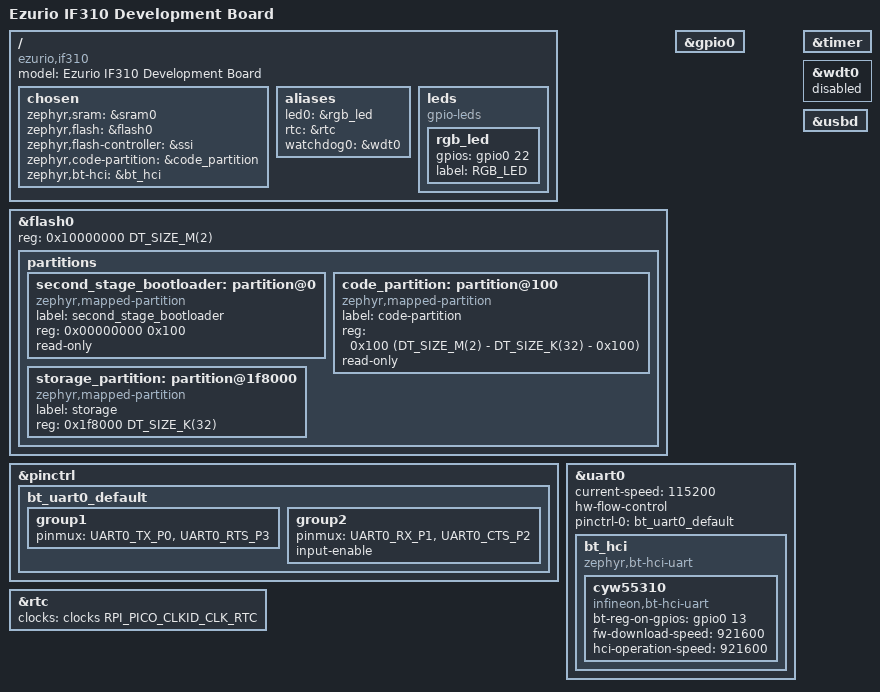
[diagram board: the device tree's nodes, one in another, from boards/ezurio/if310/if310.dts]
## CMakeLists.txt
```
cmake_minimum_required(VERSION 3.13)

set(CMAKE_EXPORT_COMPILE_COMMANDS ON)
list(APPEND BOARD_ROOT ${CMAKE_CURRENT_SOURCE_DIR})

get_filename_component(BTSTACK_ROOT "${CMAKE_CURRENT_SOURCE_DIR}/../.." ABSOLUTE)
if(DEFINED ENV{BTSTACK_ROOT})
    set(BTSTACK_ROOT "$ENV{BTSTACK_ROOT}")
endif()

include("${BTSTACK_ROOT}/chipset/bcm/btstack_bcm_patchram.cmake")

set(BTSTACK_ZEPHYR_PATCHRAM_CHIPSETS)
if(BOARD MATCHES "^if310($|/)")
    list(APPEND BTSTACK_ZEPHYR_PATCHRAM_CHIPSETS CYW55310)
elseif(BOARD MATCHES "^nucleo_(f439zi|h563zi|h753zi)($|/)")
    # Provide both firmware choices documented in the Nucleo configurations.
    list(APPEND BTSTACK_ZEPHYR_PATCHRAM_CHIPSETS CYW55513 CYW55573)
endif()

foreach(chipset IN LISTS BTSTACK_ZEPHYR_PATCHRAM_CHIPSETS)
    set(BTSTACK_ZEPHYR_PATCHRAM_FILE "${BTSTACK_${chipset}_PATCHRAM_FILE}")
    set(BTSTACK_ZEPHYR_PATCHRAM_URL "${BTSTACK_${chipset}_PATCHRAM_URL}")
    set(BTSTACK_ZEPHYR_PATCHRAM_SHA256 "${BTSTACK_${chipset}_PATCHRAM_SHA256}")
    set(BTSTACK_ZEPHYR_PATCHRAM_PATH "${CMAKE_CURRENT_SOURCE_DIR}/${BTSTACK_ZEPHYR_PATCHRAM_FILE}")
    if(NOT EXISTS "${BTSTACK_ZEPHYR_PATCHRAM_PATH}")
        message(STATUS "Downloading ${BTSTACK_ZEPHYR_PATCHRAM_FILE}")
        file(DOWNLOAD
            "${BTSTACK_ZEPHYR_PATCHRAM_URL}"
            "${BTSTACK_ZEPHYR_PATCHRAM_PATH}"
            EXPECTED_HASH SHA256=${BTSTACK_ZEPHYR_PATCHRAM_SHA256}
            STATUS BTSTACK_ZEPHYR_PATCHRAM_DOWNLOAD_STATUS)
        list(GET BTSTACK_ZEPHYR_PATCHRAM_DOWNLOAD_STATUS 0 BTSTACK_ZEPHYR_PATCHRAM_DOWNLOAD_RESULT)
        if(NOT BTSTACK_ZEPHYR_PATCHRAM_DOWNLOAD_RESULT EQUAL 0)
            list(GET BTSTACK_ZEPHYR_PATCHRAM_DOWNLOAD_STATUS 1 BTSTACK_ZEPHYR_PATCHRAM_DOWNLOAD_ERROR)
            file(REMOVE "${BTSTACK_ZEPHYR_PATCHRAM_PATH}")
            message(FATAL_ERROR "Failed to download ${BTSTACK_ZEPHYR_PATCHRAM_FILE}: ${BTSTACK_ZEPHYR_PATCHRAM_DOWNLOAD_ERROR}")
        endif()
    endif()
endforeach()

find_package(Zephyr REQUIRED HINTS $ENV{ZEPHYR_BASE})
project(BTstack-Zephyr)

find_package(Python3 REQUIRED COMPONENTS Interpreter)
include("${BTSTACK_ROOT}/tool/cmake/BTstack.cmake")
include("${BTSTACK_ROOT}/example/requirements.cmake")

btstack_declare_port(zephyr)
btstack_collect_public_include_directories(BTSTACK_ZEPHYR_PUBLIC_INCLUDE_DIRECTORIES)

# Zephyr normally force-includes autoconf.h for compilation. Include it
# explicitly while extracting btstack_config.h's ENABLE_*/HAVE_* macros so the
# resolver sees the same Kconfig values as the compiler.
btstack_configure_port(OUTPUT BTSTACK_ZEPHYR_CONFIGURATION_MACROS
    CONFIG "${CMAKE_CURRENT_SOURCE_DIR}/btstack_config.h"
    INCLUDE_DIRECTORIES "${CMAKE_CURRENT_BINARY_DIR}/zephyr/include/generated")
# Zephyr normally reconfigures after Kconfig changes; retain the generated
# header explicitly because it directly controls resolver selection.
set_property(DIRECTORY APPEND PROPERTY CMAKE_CONFIGURE_DEPENDS
    "${CMAKE_CURRENT_BINARY_DIR}/zephyr/include/generated/zephyr/autoconf.h")

string(JOIN ", " BTSTACK_ZEPHYR_CONFIGURATION_MACROS_DISPLAY ${BTSTACK_ZEPHYR_CONFIGURATION_MACROS})
message(STATUS "BTstack config ENABLE_*/HAVE_* macros: ${BTSTACK_ZEPHYR_CONFIGURATION_MACROS_DISPLAY}")

if(DEFINED BTSTACK_ZEPHYR_EXAMPLE AND NOT "${BTSTACK_ZEPHYR_EXAMPLE}" STREQUAL "")
    set(BTSTACK_ZEPHYR_EXAMPLE "${BTSTACK_ZEPHYR_EXAMPLE}")
elseif(DEFINED ENV{EXAMPLE} AND NOT "$ENV{EXAMPLE}" STREQUAL "")
    set(BTSTACK_ZEPHYR_EXAMPLE "$ENV{EXAMPLE}")
else()
    set(BTSTACK_ZEPHYR_EXAMPLE gatt_counter)
endif()

btstack_filter_examples_for_port(BTSTACK_ZEPHYR_EXAMPLES
    CANDIDATES ${btstack_declared_applications})

list(FIND btstack_declared_applications "${BTSTACK_ZEPHYR_EXAMPLE}" BTSTACK_ZEPHYR_EXAMPLE_INDEX)
if(BTSTACK_ZEPHYR_EXAMPLE_INDEX EQUAL -1)
    message(FATAL_ERROR "Unknown Zephyr example '${BTSTACK_ZEPHYR_EXAMPLE}'")
endif()
list(FIND BTSTACK_ZEPHYR_EXAMPLES "${BTSTACK_ZEPHYR_EXAMPLE}" BTSTACK_ZEPHYR_ENABLED_EXAMPLE_INDEX)
if(BTSTACK_ZEPHYR_ENABLED_EXAMPLE_INDEX EQUAL -1)
    message(FATAL_ERROR
        "Zephyr example '${BTSTACK_ZEPHYR_EXAMPLE}' is not enabled by btstack_config.h. "
        "Run 'cmake --build <build-dir> --target port-info' for the available configuration.")
endif()

# src/main.c always installs the Zephyr HCI transport, flash-backed TLV
# implementation, and the optional LE/Classic databases. Feature-gated groups
# are pruned by btstack_filter_groups_for_port.
set(BTSTACK_ZEPHYR_BASE_GROUPS
    core
    chipset-zephyr
    le-device-db-tlv
    link-key-db-tlv
    tlv-none
    platform-embedded-tlv-flash-bank
    third-party-micro-ecc
    third-party-rijndael)

set(BTSTACK_ZEPHYR_PORT_SOURCES
    "${BTSTACK_ROOT}/platform/zephyr/btstack_run_loop_zephyr.c"
    "${BTSTACK_ROOT}/platform/zephyr/hal_flash_bank_zephyr.c"
    "${BTSTACK_ROOT}/platform/zephyr/hci_transport_zephyr.c")

# Match the toolchain settings that Zephyr applies to its own targets.
zephyr_get_include_directories_for_lang(C includes)
zephyr_get_system_include_directories_for_lang(C system_includes)
zephyr_get_compile_definitions_for_lang(C definitions)
zephyr_get_compile_options_for_lang(C options)
set(external_project_cflags
    ${includes}$<SEMICOLON>${definitions}$<SEMICOLON>${options}$<SEMICOLON>${system_includes})
string(REGEX REPLACE "\\$<TARGET_PROPERTY:compiler,imacros>\\$<SEMICOLON>([^\\$]+)"
    "\$<1:SHELL:-imacros \\1>"
    BTSTACK_ZEPHYR_COMPILE_OPTIONS "${external_project_cflags}")

btstack_add_application_library(
    TARGET btstack_zephyr
    APPLICATION ${BTSTACK_ZEPHYR_EXAMPLE}
    BASE_GROUPS ${BTSTACK_ZEPHYR_BASE_GROUPS}
    PORT_SOURCES ${BTSTACK_ZEPHYR_PORT_SOURCES}
    PUBLIC_INCLUDE_DIRECTORIES
        ${BTSTACK_ZEPHYR_PUBLIC_INCLUDE_DIRECTORIES}
        "${CMAKE_CURRENT_SOURCE_DIR}"
        "${CMAKE_CURRENT_BINARY_DIR}"
        "${BTSTACK_ROOT}/chipset/zephyr"
        "${BTSTACK_ROOT}/platform/embedded"
        "${BTSTACK_ROOT}/platform/zephyr"
    PRIVATE_COMPILE_OPTIONS ${BTSTACK_ZEPHYR_COMPILE_OPTIONS})
# The BTstack library is external to Zephyr's normal app target dependency
# chain. Wait for both the standard interface and generated headers (including
# heap_constants.h, which upstream Zephyr creates separately).
add_dependencies(btstack_zephyr zephyr_interface zephyr_generated_headers)

set(BTSTACK_ZEPHYR_APPLICATION_SOURCES
    "${CMAKE_CURRENT_SOURCE_DIR}/src/main.c")
btstack_get_application_property(application_sources "${BTSTACK_ZEPHYR_EXAMPLE}" SOURCES)
btstack_get_application_property(application_gatt "${BTSTACK_ZEPHYR_EXAMPLE}" GATT_DB)
foreach(source IN LISTS application_sources)
    list(APPEND BTSTACK_ZEPHYR_APPLICATION_SOURCES "${source}")
endforeach()
target_sources(app PRIVATE ${BTSTACK_ZEPHYR_APPLICATION_SOURCES})
target_include_directories(app PRIVATE "${CMAKE_CURRENT_BINARY_DIR}")

if(application_gatt)
    message(STATUS "Zephyr example ${BTSTACK_ZEPHYR_EXAMPLE} -- with GATT DB")
    btstack_target_gatt(app
        "${application_gatt}")
else()
    message(STATUS "Zephyr example ${BTSTACK_ZEPHYR_EXAMPLE}")
endif()
target_link_libraries(app PRIVATE btstack_zephyr)

# Register a complete source and include closure for every supported example.
# Zephyr builds one application at a time, so only the selected one needs a
# library target during this configure pass.
foreach(example IN LISTS BTSTACK_ZEPHYR_EXAMPLES)
    btstack_resolve_example_for_port(zephyr "${example}" example_groups example_configuration)
    btstack_filter_groups_for_port(example_base_groups
        GROUPS ${BTSTACK_ZEPHYR_BASE_GROUPS})
    btstack_resolve_groups(example_all_groups
        GROUPS ${example_groups} ${example_base_groups})
    btstack_collect_sources(example_sources
        GROUPS ${example_all_groups})
    list(APPEND example_sources
        ${BTSTACK_ZEPHYR_PORT_SOURCES}
        "${CMAKE_CURRENT_SOURCE_DIR}/src/main.c")
    btstack_get_application_property(application_sources "${example}" SOURCES)
    foreach(source IN LISTS application_sources)
        list(APPEND example_sources "${source}")
    endforeach()
    list(REMOVE_DUPLICATES example_sources)
    list(SORT example_sources)
    string(REPLACE "-" "_" example_suffix "${example}")
    set_property(GLOBAL PROPERTY "btstack_info_zephyr_${example_suffix}_sources" "${example_sources}")

    btstack_collect_include_directories(example_group_include_directories
        GROUPS ${example_all_groups})
    set(example_include_directories
        ${BTSTACK_ZEPHYR_PUBLIC_INCLUDE_DIRECTORIES}
        ${example_group_include_directories}
        "${CMAKE_CURRENT_SOURCE_DIR}"
        "${CMAKE_CURRENT_BINARY_DIR}"
        "${BTSTACK_ROOT}/chipset/zephyr"
        "${BTSTACK_ROOT}/platform/embedded"
        "${BTSTACK_ROOT}/platform/zephyr")
    list(REMOVE_DUPLICATES example_include_directories)
    list(SORT example_include_directories)
    set_property(GLOBAL PROPERTY
        "btstack_info_zephyr_${example_suffix}_include_directories"
        "${example_include_directories}")
endforeach()

btstack_add_info_targets()
```

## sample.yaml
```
sample:
  name: Bluetooth btstack
tests:
  sample.bluetooth.btstack:
    harness: bluetooth
    platform_allow:
      - bbc_microbit
      - qemu_x86
      - nrf52840dk_nrf52840
    integration_platforms:
      - qemu_x86
    tags: bluetooth
```

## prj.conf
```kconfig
# Debug output
#CONFIG_CONSOLE=y
#CONFIG_STDOUT_CONSOLE=y
CONFIG_UART_CONSOLE=n
CONFIG_RTT_CONSOLE=y
CONFIG_USE_SEGGER_RTT=y
#CONFIG_GPIO=y
#CONFIG_SERIAL=y
#CONFIG_UART_INTERRUPT_DRIVEN=y
CONFIG_NEWLIB_LIBC=y

CONFIG_FLASH=y
CONFIG_FLASH_MAP=y

CONFIG_I2C=n
CONFIG_WATCHDOG=n
CONFIG_SPI=n
CONFIG_SERIAL=n

CONFIG_PM=n

CONFIG_DYNAMIC_INTERRUPTS=n
CONFIG_IRQ_OFFLOAD=n
CONFIG_POLL=y

CONFIG_BOOT_BANNER=n
CONFIG_BOOT_DELAY=0

CONFIG_SIZE_OPTIMIZATIONS=y
CONFIG_ARM_MPU=n

CONFIG_BT=y
CONFIG_BT_HCI_RAW=y

# Setup connections
CONFIG_BT_MAX_CONN=16

# Setup CMD and Event buffer
CONFIG_BT_BUF_CMD_TX_SIZE=255
CONFIG_BT_BUF_EVT_DISCARDABLE_SIZE=255
# CONFIG_BT_BUF_EVT_RX_COUNT must be greater than CONFIG_BT_BUF_ACL_TX_COUNT
CONFIG_BT_BUF_EVT_RX_COUNT=16

# Setup ACL Buffer
CONFIG_BT_BUF_ACL_RX_SIZE=251
CONFIG_BT_BUF_ACL_TX_SIZE=251
CONFIG_BT_BUF_ACL_TX_COUNT=10

CONFIG_BT_RX_STACK_SIZE=1024
CONFIG_BT_HCI_TX_STACK_SIZE_WITH_PROMPT=y
CONFIG_BT_HCI_TX_STACK_SIZE=640
CONFIG_SYSTEM_WORKQUEUE_STACK_SIZE=512
#CONFIG_MPSL_WORK_STACK_SIZE=640
CONFIG_MAIN_STACK_SIZE=4096
CONFIG_IDLE_STACK_SIZE=128
CONFIG_ISR_STACK_SIZE=1024

#CONFIG_THREAD_ANALYZER=y
#CONFIG_THREAD_ANALYZER_USE_PRINTK=y
#CONFIG_THREAD_ANALYZER_AUTO=y
#CONFIG_THREAD_ANALYZER_AUTO_INTERVAL=5
#CONFIG_THREAD_NAME=y

# Workaround: Unable to allocate command buffer when using K_NO_WAIT since
# Host number of completed commands does not follow normal flow control.
#CONFIG_BT_BUF_CMD_TX_COUNT=10
```

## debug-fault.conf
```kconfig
# Extra diagnostics for debugging faults with a debugger or console.
CONFIG_FAULT_DUMP=2
CONFIG_ASSERT=y
CONFIG_THREAD_NAME=y
CONFIG_INIT_STACKS=y
CONFIG_STACK_SENTINEL=y
```

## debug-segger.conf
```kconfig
# Console output via SEGGER RTT.
CONFIG_CONSOLE=y
CONFIG_STDOUT_CONSOLE=y
CONFIG_UART_CONSOLE=n
CONFIG_RTT_CONSOLE=y
CONFIG_USE_SEGGER_RTT=y
```

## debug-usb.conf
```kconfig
# Console output via the board's CDC ACM console devicetree node.
CONFIG_CONSOLE=y
CONFIG_STDOUT_CONSOLE=y
CONFIG_UART_CONSOLE=y
CONFIG_RTT_CONSOLE=n
CONFIG_USE_SEGGER_RTT=n
CONFIG_USB_DEVICE_STACK=y
CONFIG_USB_DEVICE_INITIALIZE_AT_BOOT=y
CONFIG_UART_LINE_CTRL=y
```

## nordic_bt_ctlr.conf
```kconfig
# Nordic Bluetooth Controller options.
CONFIG_BT_CTLR_ASSERT_HANDLER=y
CONFIG_BT_CTLR_DATA_LENGTH_MAX=251
CONFIG_BT_CTLR_PHY_2M=y
CONFIG_BT_CTLR_PHY_CODED=y
CONFIG_BT_CTLR_PRIVACY=n
```

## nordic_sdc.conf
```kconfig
# Nordic SoftDevice Controller configuration

# Nordic SoCs use LE-only Controllers.
CONFIG_BTSTACK_ENABLE_BLE=y

CONFIG_BT_CTLR_SDC_TX_PACKET_COUNT=10

CONFIG_BT_CTLR_ASSERT_HANDLER=y

#CONFIG_BT_CTLR_DTM_HCI=y
CONFIG_BT_ISO_BROADCASTER=y

# Enable optional Controller features
CONFIG_BT_CTLR_DATA_LENGTH_MAX=251
CONFIG_BT_CTLR_PHY_2M=y
CONFIG_BT_CTLR_PHY_CODED=y
CONFIG_BT_CTLR_PRIVACY=n
```

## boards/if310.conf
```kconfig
# HCI H:4 UART transport to the IF310 module.
CONFIG_SERIAL=y
CONFIG_UART_INTERRUPT_DRIVEN=y

# IF310 uses a dual-mode CYW55310 Controller.
CONFIG_BTSTACK_ENABLE_BLE=y
CONFIG_BTSTACK_ENABLE_CLASSIC=y

# Download CYW55310 PatchRAM at boot.
CONFIG_BT_AIROC_CUSTOM=y
CONFIG_AIROC_CUSTOM_FIRMWARE_HCD_BLOB="CYW55500A1_001.002.032.0211.0125.hcd"
CONFIG_AIROC_AUTOBAUD_MODE=y

# IF310 uses a dual-mode controller, so use BR/EDR maximum sized ACL buffers.
CONFIG_BT_BUF_ACL_RX_SIZE=1021
CONFIG_BT_BUF_ACL_TX_SIZE=1021

CONFIG_BT_ISO_BROADCASTER=y
CONFIG_MAIN_STACK_SIZE=8192
```

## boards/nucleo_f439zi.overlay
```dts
/ {
    chosen {
        zephyr,code-partition = &image_partition;
        zephyr,bt-hci = &bt_hci;
    };
};

&usart2 {
    status = "okay";
    /* The UART bus speed (current_speed) for zephyr_bt_uart should be the same
     * as the default baudrate defined in CYW43xx firmware (default 115200).
     */

    current-speed = <115200>;
    hw-flow-control;

    /* HCI-UART pins*/
    pinctrl-0 = <&usart2_rx_pd6 &usart2_tx_pd5 &usart2_rts_pd4 &usart2_cts_pd3>;
    pinctrl-names = "default";

    bt_hci: bt_hci {
        status = "okay";
        compatible = "zephyr,bt-hci-uart";

        cyw555xx {
        compatible = "infineon,cyw43xxx-bt-hci";
        bt-reg-on-gpios = <&gpiog 3 GPIO_ACTIVE_HIGH>;

        /* Configuration UART speeds for firmware download (fw-download-speed) and
         * HCI operation (hci-operation-speed).
         * If hci-operation-speed or fw-download-speed are not defined in bt-hci{...}
         * node, cyw43xx driver will use bus/current-speed as default speed.
         */
        fw-download-speed   = <921600>;
        hci-operation-speed = <921600>;
        };
    };
};

&flash0 {
//    /delete-propety/ partitions;
    partitions {
        compatible = "fixed-partitions";
		#address-cells = <1>;
		#size-cells = <1>;

        /* application image slot: 2016KB */
        image_partition: partition@0 {
			label = "image";
			reg = <0x00000000 DT_SIZE_K(2016)>;
			read-only;
		};

	    /* storage slot: 32KB */
	    storage_partition: partition@1F8000 {
            label = "storage";
		    reg = <0x001F8000 DT_SIZE_K(32)>;
	    };
	};
};
```

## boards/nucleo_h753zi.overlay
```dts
/ {
    chosen {
        zephyr,code-partition = &image_partition;
    };
};

&flash0 {
    /delete-node/ partitions;
    partitions {
        compatible = "fixed-partitions";
		#address-cells = <1>;
		#size-cells = <1>;

        /* application image slot: 2016KB */
        image_partition: partition@0 {
			label = "image";
			reg = <0x00000000 DT_SIZE_K(2016)>;
			read-only;
		};

	    /* storage slot: 32KB */
	    storage_partition: partition@1F8000 {
            label = "storage";
		    reg = <0x001F8000 DT_SIZE_K(32)>;
	    };
	};
};
```

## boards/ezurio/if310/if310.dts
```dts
/*
 * SPDX-License-Identifier: Apache-2.0
 */

/dts-v1/;

#include <freq.h>
#include <raspberrypi/rpi_pico/rp2040.dtsi>
#include <zephyr/dt-bindings/gpio/gpio.h>
#include <zephyr/dt-bindings/pinctrl/rpi-pico-rp2040-pinctrl.h>

/ {
	model = "Ezurio IF310 Development Board";
	compatible = "ezurio,if310";

	chosen {
		zephyr,sram = &sram0;
		zephyr,flash = &flash0;
		zephyr,flash-controller = &ssi;
		zephyr,code-partition = &code_partition;
		zephyr,bt-hci = &bt_hci;
	};

	aliases {
		led0 = &rgb_led;
		rtc = &rtc;
		watchdog0 = &wdt0;
	};

	leds {
		compatible = "gpio-leds";

		rgb_led: rgb_led {
			gpios = <&gpio0 22 GPIO_ACTIVE_HIGH>;
			label = "RGB_LED";
		};
	};
};

&flash0 {
	reg = <0x10000000 DT_SIZE_M(2)>;
	ranges = <0x0 0x10000000 DT_SIZE_M(2)>;

	partitions {
		ranges;
		#address-cells = <1>;
		#size-cells = <1>;

		second_stage_bootloader: partition@0 {
			compatible = "zephyr,mapped-partition";
			label = "second_stage_bootloader";
			reg = <0x00000000 0x100>;
			read-only;
		};

		code_partition: partition@100 {
			compatible = "zephyr,mapped-partition";
			label = "code-partition";
			reg = <0x100 (DT_SIZE_M(2) - DT_SIZE_K(32) - 0x100)>;
			read-only;
		};

		storage_partition: partition@1f8000 {
			compatible = "zephyr,mapped-partition";
			label = "storage";
			reg = <0x1f8000 DT_SIZE_K(32)>;
		};
	};
};

&pinctrl {
	bt_uart0_default: bt_uart0_default {
		group1 {
			pinmux = <UART0_TX_P0>, <UART0_RTS_P3>;
		};
		group2 {
			pinmux = <UART0_RX_P1>, <UART0_CTS_P2>;
			input-enable;
		};
	};
};

&gpio0 {
	status = "okay";
};

&uart0 {
	status = "okay";
	current-speed = <115200>;
	hw-flow-control;
	pinctrl-0 = <&bt_uart0_default>;
	pinctrl-names = "default";

	bt_hci: bt_hci {
		status = "okay";
		compatible = "zephyr,bt-hci-uart";

		cyw55310 {
			status = "okay";
			compatible = "infineon,bt-hci-uart";
			bt-reg-on-gpios = <&gpio0 13 GPIO_ACTIVE_HIGH>;
			fw-download-speed = <921600>;
			hci-operation-speed = <921600>;
		};
	};
};

&timer {
	status = "okay";
};

&wdt0 {
	status = "disabled";
};

&rtc {
	clocks = <&clocks RPI_PICO_CLKID_CLK_RTC>;
	status = "okay";
};

zephyr_udc0: &usbd {
	status = "okay";
};
```

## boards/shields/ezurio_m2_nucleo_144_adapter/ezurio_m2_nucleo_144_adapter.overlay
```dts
/ {
    chosen {
        zephyr,bt-hci = &bt_hci;
    };
};

&usart2 {
    status = "okay";
    /* The UART bus speed (current_speed) for zephyr_bt_uart should be the same
     * as the default baudrate defined in CYW43xx firmware (default 115200).
     */

    current-speed = <115200>;
    hw-flow-control;

    /* HCI-UART pins*/
    pinctrl-0 = <&usart2_rx_pd6 &usart2_tx_pd5 &usart2_rts_pd4 &usart2_cts_pd3>;
    pinctrl-names = "default";

    bt_hci: bt_hci {
        status = "okay";
        compatible = "zephyr,bt-hci-uart";

        cyw555xx {
        compatible = "infineon,cyw43xxx-bt-hci";
        bt-reg-on-gpios = <&gpiog 3 GPIO_ACTIVE_HIGH>;

        /* Configuration UART speeds for firmware download (fw-download-speed) and
         * HCI operation (hci-operation-speed).
         * If hci-operation-speed or fw-download-speed are not defined in bt-hci{...}
         * node, cyw43xx driver will use bus/current-speed as default speed.
         */
        fw-download-speed   = <921600>;
        hci-operation-speed = <921600>;
        };
    };
};
```

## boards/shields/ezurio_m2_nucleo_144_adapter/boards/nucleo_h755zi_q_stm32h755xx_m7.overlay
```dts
&usart2 {
    bt_hci: bt_hci {
        cyw555xx {
        bt-reg-on-gpios = <&gpiog 8 GPIO_ACTIVE_HIGH>;
        };
    };
};
```

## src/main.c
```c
/*
 * Copyright (c) 2016 Nordic Semiconductor ASA
 * Copyright (c) 2015-2016 Intel Corporation
 *
 * SPDX-License-Identifier: Apache-2.0
 */

#include <errno.h>
#include <stddef.h>
#include <stdio.h>
#include <string.h>

#include <zephyr/storage/flash_map.h>

#if DT_NODE_HAS_COMPAT(DT_CHOSEN(zephyr_console), zephyr_cdc_acm_uart)
#include <zephyr/device.h>
#include <zephyr/drivers/uart.h>
#include <zephyr/kernel.h>
#endif

// Nordic SDK
#if defined(CONFIG_SOC_SERIES_NRF53X)
#include <nrfx_clock.h>
#endif

// BTstack
#include "btstack_debug.h"
#include "btstack_event.h"
#include "btstack_memory.h"
#include "hci.h"
#include "hci_dump.h"
#ifdef ENABLE_HCI_DUMP
#ifdef ENABLE_SEGGER_RTT_BINARY
#include "hci_dump_segger_rtt_binary.h"
#else
#include "hci_dump_embedded_stdout.h"
#endif
#endif
#include "hci_transport.h"

#include "bluetooth_company_id.h"
#include "btstack_chipset_zephyr.h"

#include "btstack_tlv.h"
#include "btstack_tlv_none.h"
#ifdef ENABLE_CLASSIC
#include "classic/btstack_link_key_db_tlv.h"
#endif
#ifdef ENABLE_BLE
#include "ble/le_device_db_tlv.h"
#endif

#include "hci_transport_zephyr.h"
#include "btstack_run_loop_zephyr.h"

#include "hal_flash_bank_zephyr.h"
#include "btstack_tlv_flash_bank.h"

// Zephyr renamed the fixed-partition helpers. Prefer the replacement macros
// to avoid deprecation warnings while retaining support for older Zephyr SDKs.
#if defined(PARTITION_EXISTS)
#define BTSTACK_PARTITION_EXISTS(label) PARTITION_EXISTS(label)
#define BTSTACK_PARTITION_OFFSET(label) PARTITION_OFFSET(label)
#define BTSTACK_PARTITION_SIZE(label)   PARTITION_SIZE(label)
#else
#define BTSTACK_PARTITION_EXISTS(label) FIXED_PARTITION_EXISTS(label)
#define BTSTACK_PARTITION_OFFSET(label) FIXED_PARTITION_OFFSET(label)
#define BTSTACK_PARTITION_SIZE(label)   FIXED_PARTITION_SIZE(label)
#endif

// Uncomment to wait during startup for USB CDC console to be ready
// #define ENABLE_USB_CDC_WAIT

static btstack_packet_callback_registration_t hci_event_callback_registration;

static bd_addr_t local_addr = { 0 };
#ifdef ENABLE_BLE
static bd_addr_t local_le_random_addr = { 0 };
static bool local_le_random_addr_set;
#endif

static void print_local_addr(void){
#ifdef ENABLE_BLE
    if (local_le_random_addr_set){
        printf("BTstack up and running on %s (random).\n", bd_addr_to_str(local_le_random_addr));
        return;
    }
#endif
    gap_local_bd_addr(local_addr);
    printf("BTstack up and running on %s.\n", bd_addr_to_str(local_addr));
}

static void local_version_information_handler(uint8_t * packet){
    printf("Local version information:\n");
    uint16_t hci_version    = packet[6];
    uint16_t hci_revision   = little_endian_read_16(packet, 7);
    uint16_t lmp_version    = packet[9];
    uint16_t manufacturer   = little_endian_read_16(packet, 10);
    uint16_t lmp_subversion = little_endian_read_16(packet, 12);
    printf("- HCI Version    %#04x\n", hci_version);
    printf("- HCI Revision   %#04x\n", hci_revision);
    printf("- LMP Version    %#04x\n", lmp_version);
    printf("- LMP Subversion %#04x\n", lmp_subversion);
    printf("- Manufacturer   %#04x\n", manufacturer);
    switch (manufacturer){
        case BLUETOOTH_COMPANY_ID_NORDIC_SEMICONDUCTOR_ASA:
        case BLUETOOTH_COMPANY_ID_THE_LINUX_FOUNDATION:
            printf("Nordic Semiconductor nRF5 chipset.\n");
            hci_set_chipset(btstack_chipset_zephyr_instance());
            break;
        case BLUETOOTH_COMPANY_ID_BROADCOM_CORPORATION:
        case BLUETOOTH_COMPANY_ID_CYPRESS_SEMICONDUCTOR:
        case BLUETOOTH_COMPANY_ID_INFINEON_TECHNOLOGIES_AG:
            printf("Broadcom/Cypress/Infineon Controller.\n");
            break;
        default:
            printf("Unknown manufacturer.\n");
            break;
    }
}

static void packet_handler (uint8_t packet_type, uint16_t channel, uint8_t *packet, uint16_t size){
    const uint8_t *params;
    if (packet_type != HCI_EVENT_PACKET) return;
    switch (hci_event_packet_get_type(packet)){
        case BTSTACK_EVENT_STATE:
            switch(btstack_event_state_get_state(packet)){
                case HCI_STATE_WORKING:
                    print_local_addr();
                    break;
                case HCI_STATE_OFF:
                    log_info("Good bye, see you.\n");
                    break;
                default:
                    break;
            }
            break;
        case HCI_EVENT_COMMAND_COMPLETE:
            switch (hci_event_command_complete_get_command_opcode(packet)){
                case HCI_OPCODE_HCI_READ_LOCAL_VERSION_INFORMATION:
                    local_version_information_handler(packet);
                    break;
                case HCI_OPCODE_HCI_ZEPHYR_READ_STATIC_ADDRESS:
#ifdef ENABLE_BLE
                    params = hci_event_command_complete_get_return_parameters(packet);
                    if(params[0] != 0)
                        break;
                    if(params[1] == 0)
                        break;
                    if(size < 13)
                        break;
                    printf("Use static random address reported by Zephyr Controller.\n");
                    reverse_48(&params[2], local_le_random_addr);
                    local_le_random_addr_set = true;
                    gap_random_address_set(local_le_random_addr);
#endif
                    break;
                default:
                    break;
            }
            break;
        default:
            break;
    }
}

int btstack_main(void);

#if defined(CONFIG_BT_CTLR_ASSERT_HANDLER)
void bt_ctlr_assert_handle(char *file, uint32_t line)
{
    printf("CONFIG_BT_CTLR_ASSERT_HANDLER: file %s, line %u\n", file, line);
    while (1) {
    }
}
#endif /* CONFIG_BT_CTLR_ASSERT_HANDLER */

static hal_flash_bank_zephyr_t  hal_flash_bank_context;
static btstack_tlv_flash_bank_t btstack_tlv_flash_bank_context;

#if defined(ENABLE_USB_CDC_WAIT) && DT_NODE_HAS_COMPAT(DT_CHOSEN(zephyr_console), zephyr_cdc_acm_uart)
static void wait_for_usb_cdc_console(void)
{
    const struct device * console = DEVICE_DT_GET(DT_CHOSEN(zephyr_console));
    uint32_t dtr = 0;

    if (!device_is_ready(console)) {
        return;
    }

    while (!dtr) {
        uart_line_ctrl_get(console, UART_LINE_CTRL_DTR, &dtr);
        k_sleep(K_MSEC(100));
    }
}
#else
static void wait_for_usb_cdc_console(void)
{
}
#endif

int main(void)
{
#if defined(CONFIG_SOC_SERIES_NRF53X)
    // switch the nrf5340_cpuapp to 128MHz
    nrfx_clock_divider_set(NRF_CLOCK_DOMAIN_HFCLK, NRF_CLOCK_HFCLK_DIV_1);
#endif

    wait_for_usb_cdc_console();

    printf("BTstack booting up...\n");

    // start with BTstack init - especially configure HCI Transport
    btstack_memory_init();
    btstack_run_loop_init(btstack_run_loop_zephyr_get_instance());
#ifdef ENABLE_HCI_DUMP
    // enable full log output while porting
#ifdef ENABLE_SEGGER_RTT_BINARY
    hci_dump_segger_rtt_binary_open( HCI_DUMP_PACKETLOGGER );
    hci_dump_init(hci_dump_segger_rtt_binary_get_instance());
#else
    hci_dump_init(hci_dump_embedded_stdout_get_instance());
#endif
#endif

#if defined(CONFIG_FLASH) && \
    DT_HAS_CHOSEN(zephyr_code_partition) && \
    BTSTACK_PARTITION_EXISTS(storage_partition)

    // setup TLV
    uint32_t bank_size = BTSTACK_PARTITION_SIZE(storage_partition)/2;
    uint32_t bank_0_addr = BTSTACK_PARTITION_OFFSET(storage_partition);
    uint32_t bank_1_addr = bank_0_addr+bank_size;
    printf("configure persistent TLV storage:\n");
    printf("    bank_size:   %8d\n", bank_size);
    printf("    bank_0_addr: %08x\n", bank_0_addr);
    printf("    bank_1_addr: %08x\n", bank_1_addr);
    const hal_flash_bank_t * hal_flash_bank_impl = hal_flash_bank_zephyr_init_instance(
            &hal_flash_bank_context,
            bank_size,
            16,
            bank_0_addr,
            bank_1_addr);
    const btstack_tlv_t * btstack_tlv_impl = btstack_tlv_flash_bank_init_instance(
            &btstack_tlv_flash_bank_context,
            hal_flash_bank_impl,
            &hal_flash_bank_context);
#else
    const btstack_tlv_t * btstack_tlv_impl = btstack_tlv_none_init_instance();
#endif
    btstack_tlv_set_instance(btstack_tlv_impl, &btstack_tlv_flash_bank_context);

#ifdef ENABLE_CLASSIC
    // setup Link Key DB using TLV
    const btstack_link_key_db_t * btstack_link_key_db = btstack_link_key_db_tlv_get_instance(btstack_tlv_impl, &btstack_tlv_flash_bank_context);
    hci_set_link_key_db(btstack_link_key_db);
#endif
#ifdef ENABLE_BLE
    // setup LE Device DB using TLV
    le_device_db_tlv_configure(btstack_tlv_impl, &btstack_tlv_flash_bank_context);
#endif

    // init HCI
    hci_init(hci_transport_zephyr_get_instance(), NULL);

    // inform about BTstack state
    hci_event_callback_registration.callback = &packet_handler;
    hci_add_event_handler(&hci_event_callback_registration);

    // hand over to btstack embedded code 
    btstack_main();

    // go
    btstack_run_loop_execute();

    while (1){};
    return 0;
}
```

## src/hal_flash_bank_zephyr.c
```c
/*
 * Copyright (C) 2017 BlueKitchen GmbH
 *
 * Redistribution and use in source and binary forms, with or without
 * modification, are permitted provided that the following conditions
 * are met:
 *
 * 1. Redistributions of source code must retain the above copyright
 *    notice, this list of conditions and the following disclaimer.
 * 2. Redistributions in binary form must reproduce the above copyright
 *    notice, this list of conditions and the following disclaimer in the
 *    documentation and/or other materials provided with the distribution.
 * 3. Neither the name of the copyright holders nor the names of
 *    contributors may be used to endorse or promote products derived
 *    from this software without specific prior written permission.
 *
 * THIS SOFTWARE IS PROVIDED BY BLUEKITCHEN GMBH AND CONTRIBUTORS
 * ``AS IS'' AND ANY EXPRESS OR IMPLIED WARRANTIES, INCLUDING, BUT NOT
 * LIMITED TO, THE IMPLIED WARRANTIES OF MERCHANTABILITY AND FITNESS
 * FOR A PARTICULAR PURPOSE ARE DISCLAIMED. IN NO EVENT SHALL BLUEKITCHEN
 * GMBH OR CONTRIBUTORS BE LIABLE FOR ANY DIRECT, INDIRECT,
 * INCIDENTAL, SPECIAL, EXEMPLARY, OR CONSEQUENTIAL DAMAGES (INCLUDING,
 * BUT NOT LIMITED TO, PROCUREMENT OF SUBSTITUTE GOODS OR SERVICES; LOSS
 * OF USE, DATA, OR PROFITS; OR BUSINESS INTERRUPTION) HOWEVER CAUSED
 * AND ON ANY THEORY OF LIABILITY, WHETHER IN CONTRACT, STRICT LIABILITY,
 * OR TORT (INCLUDING NEGLIGENCE OR OTHERWISE) ARISING IN ANY WAY OUT OF
 * THE USE OF THIS SOFTWARE, EVEN IF ADVISED OF THE POSSIBILITY OF
 * SUCH DAMAGE.
 *
 */

/*
 *  hal_flash_bank_stm32.c
 * 
 *  HAL abstraction for Flash memory that can be written anywhere
 *  after being erased
 */

#include <stdint.h>
#include <string.h> // memcpy
#include "btstack_debug.h"  // assert
#include "btstack_defines.h" // UNUSED
#include "hal_flash_bank_zephyr.h"

#include <zephyr/kernel.h>
#include <zephyr/devicetree.h>
#include <zephyr/drivers/flash.h>

static const struct device *const zephyr_flash_controller =
        DEVICE_DT_GET_OR_NULL(DT_CHOSEN(zephyr_flash_controller));

static uint32_t hal_flash_bank_zephyr_get_size(void * context){
	hal_flash_bank_zephyr_t * self = (hal_flash_bank_zephyr_t *) context;
	return self->sector_size;
}

static uint32_t hal_flash_bank_zephyr_get_alignment(void * context){
    hal_flash_bank_zephyr_t * self = (hal_flash_bank_zephyr_t *) context;
    return self->alignment;
}

static void hal_flash_bank_zephyr_erase(void * context, int bank){
    btstack_assert(bank >= 0);
    btstack_assert(bank < 2);

	hal_flash_bank_zephyr_t * self = (hal_flash_bank_zephyr_t *) context;

    int result = flash_erase(zephyr_flash_controller, self->banks[bank], self->sector_size);
    if (result != 0){
        log_error("Erase Failed, code %d.", result);
    }
}

static void hal_flash_bank_zephyr_read(void * context, int bank, uint32_t offset, uint8_t * buffer, uint32_t size){
    btstack_assert(bank >= 0);
    btstack_assert(bank < 2);

	hal_flash_bank_zephyr_t * self = (hal_flash_bank_zephyr_t *) context;

    btstack_assert(offset          <= self->sector_size);
    btstack_assert((offset + size) <= self->sector_size);

    int result = flash_read(zephyr_flash_controller, self->banks[bank] + offset, buffer, size);
    if (result != 0){
        log_error("Read Failed, bank %u, offset %u: code %d.", bank, offset, result);
    }
}

static void hal_flash_bank_zephyr_write(void * context, int bank, uint32_t offset, const uint8_t * data, uint32_t size){
    btstack_assert(bank >= 0);
    btstack_assert(bank < 2);

    hal_flash_bank_zephyr_t * self = (hal_flash_bank_zephyr_t *) context;

    btstack_assert(offset          <= self->sector_size);
    btstack_assert((offset + size) <= self->sector_size);

    int result = flash_write(zephyr_flash_controller, self->banks[bank] + offset, data, size);
    if (result != 0) {
        log_error("Write internal ERROR!, bank %u, offset %u: code %u", bank, offset, result);
    }
}

static const hal_flash_bank_t hal_flash_bank_zephyr_impl = {
    .get_size       = &hal_flash_bank_zephyr_get_size,
	.get_alignment  = &hal_flash_bank_zephyr_get_alignment,
	.erase          = &hal_flash_bank_zephyr_erase,
	.read           = &hal_flash_bank_zephyr_read,
    .write          = &hal_flash_bank_zephyr_write,
};

const hal_flash_bank_t * hal_flash_bank_zephyr_init_instance(hal_flash_bank_zephyr_t * context, uint32_t sector_size,
		uint16_t write_alignment, uintptr_t bank_0_addr, uintptr_t bank_1_addr){

    btstack_assert(write_alignment <= 16);

    /* use default: zephyr,flash-controller */
    if (!device_is_ready(zephyr_flash_controller)) {
        log_error("efault flash driver not ready");
        btstack_assert(false);
        return NULL;
    }

    context->sector_size = sector_size;
    context->alignment   = write_alignment;
	context->banks[0]    = bank_0_addr;
	context->banks[1]    = bank_1_addr;

	return &hal_flash_bank_zephyr_impl;
}
```
